# MKE15Z7 register map
Vendor: Freescale Semiconductor, Inc.; Series: Kinetis_E; File version: 1.6
CPU: CM0PLUS r0p0, little endian, no MPU, no FPU, VTOR, 2 interrupt priority bits
Registers are 32-bit, read-write, reset 0x0 unless marked. A register's access mark holds for its fields unless they carry their own. Offsets are from the block's base; [hi:lo] are bit positions; {n}, {i} and the like mark numbered series; 'fields as' and 'values as' point back to an identical list.

## OSC32 — RTC Oscillator
Base 0x40060000; register names take the prefix OSC32_
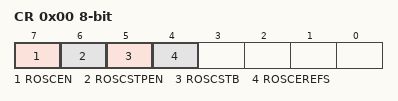
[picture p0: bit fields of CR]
0x00 CR 8-bit — RTC Oscillator Control Register
  [7] ROSCEN — RTC 32k Oscillator enable
    0=Oscillator is disabled; 1=Oscillator is enabled
  [6] ROSCSTPEN — RTC 32k Oscillator stop mode enable
    0=Oscillator is disabled regardless the state of ROSCEN; 1=Oscillator is enabled in Stop mode when ROSCEN is set
  [5] ROSCSTB ro — RTC 32k Oscillator stable flag
    0=RTC 32k oscillator is unstable now and no clock will go out of the block; 1=RTC 32k oscillator is stable
  [4] ROSCEREFS — RTC 32k Oscillator external reference clcok selection
    0=Bypass mode. RTC oscillator selects the external 32k clock.; 1=Crystal mode

## EWM — External Watchdog Monitor
Base 0x40061000; register names take the prefix EWM_
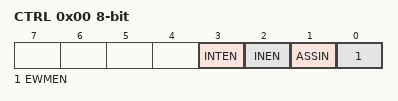
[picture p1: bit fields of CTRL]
0x00 CTRL 8-bit — Control Register
  [3] INTEN — Interrupt Enable.
  [2] INEN — Input Enable.
  [1] ASSIN — EWM_in's Assertion State Select.
  [0] EWMEN — EWM enable.
0x01 SERV 8-bit wo — Service Register
  [7:0] SERVICE — The EWM refresh mechanism requires the CPU to write two values to the SERV register: a first data byte of 0xB4, followed by a second data byte of 0x2C
0x02 CMPL 8-bit — Compare Low Register
  [7:0] COMPAREL — To prevent runaway code from changing this field, software should write to this field after a CPU reset even if the (default) minimum refresh time is required
0x03 CMPH 8-bit reset 0xFF — Compare High Register
  [7:0] COMPAREH — To prevent runaway code from changing this field, software should write to this field after a CPU reset even if the (default) maximum refresh time is required
0x05 CLKPRESCALER 8-bit — Clock Prescaler Register
  [7:0] CLK_DIV — Selected low power clock source for running the EWM counter can be prescaled as below

## TRGMUX0 — Trigger MUX Control
Base 0x40062000
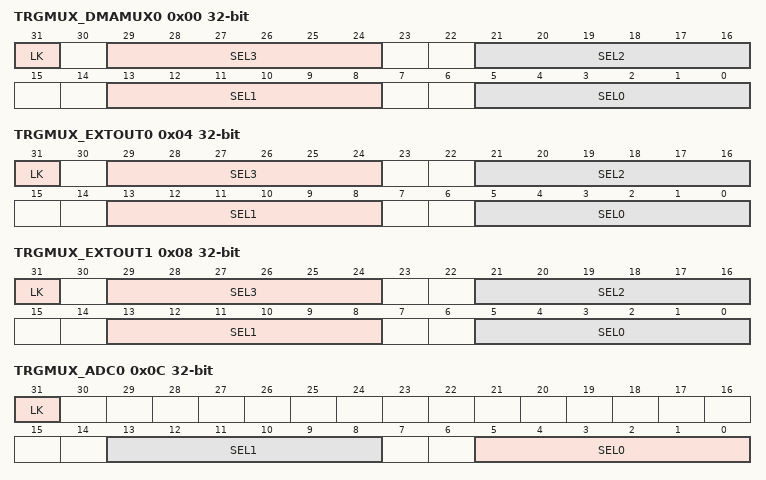
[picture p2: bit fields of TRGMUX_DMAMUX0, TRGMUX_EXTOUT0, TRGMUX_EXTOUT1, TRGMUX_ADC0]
0x00 TRGMUX_DMAMUX0 — TRGMUX Register
  [31] LK ro — Enable
    0=Register can be written; 1=Register cannot be written until the next system Reset
  [8n+5:8n] SEL{n} (n=0..3) — Trigger MUX Input {n} Source Select
0x04 TRGMUX_EXTOUT0 — TRGMUX Register
  fields as TRGMUX_DMAMUX0
0x08 TRGMUX_EXTOUT1 — TRGMUX Register
  fields as TRGMUX_DMAMUX0
0x0C TRGMUX_ADC0 — TRGMUX Register
  [31] LK ro — Enable
    values as TRGMUX_DMAMUX0.LK
  [13:8] SEL1 — Trigger MUX Input 1 Source Select
  [5:0] SEL0 — Trigger MUX Input 0 Source Select
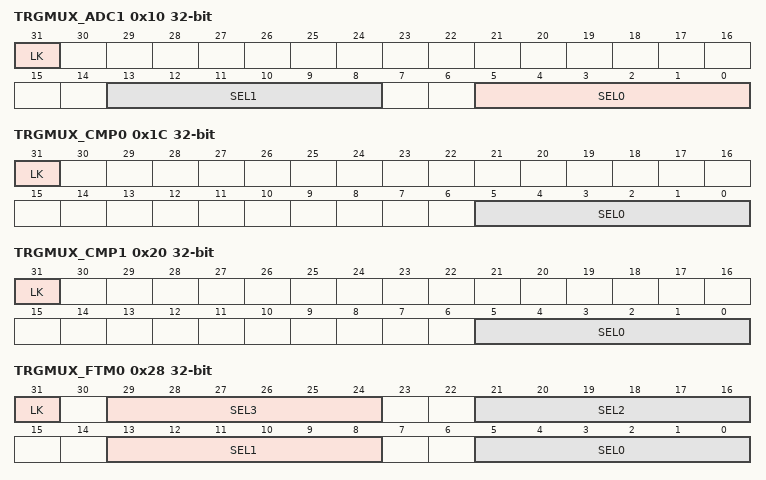
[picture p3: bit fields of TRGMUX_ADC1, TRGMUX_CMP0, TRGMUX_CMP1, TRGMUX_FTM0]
0x10 TRGMUX_ADC1 — TRGMUX Register
  fields as TRGMUX_ADC0
0x1C TRGMUX_CMP0 — TRGMUX Register
  [31] LK ro — Enable
    values as TRGMUX_DMAMUX0.LK
  [5:0] SEL0 — Trigger MUX Input 0 Source Select
0x20 TRGMUX_CMP1 — TRGMUX Register
  fields as TRGMUX_CMP0
0x28 TRGMUX_FTM0 — TRGMUX Register
  fields as TRGMUX_DMAMUX0
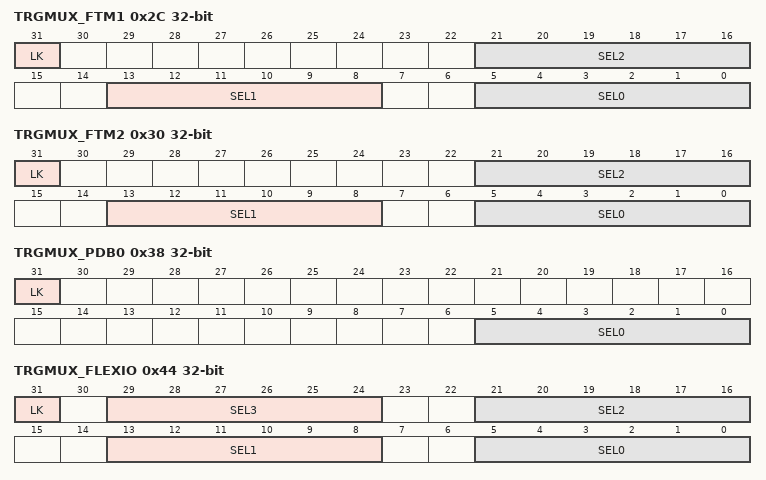
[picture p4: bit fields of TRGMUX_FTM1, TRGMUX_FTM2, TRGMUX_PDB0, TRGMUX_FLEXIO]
0x2C TRGMUX_FTM1 — TRGMUX Register
  [31] LK ro — Enable
    values as TRGMUX_DMAMUX0.LK
  [21:16] SEL2 — Trigger MUX Input 2 Source Select
  [13:8] SEL1 — Trigger MUX Input 1 Source Select
  [5:0] SEL0 — Trigger MUX Input 0 Source Select
0x30 TRGMUX_FTM2 — TRGMUX Register
  fields as TRGMUX_FTM1
0x38 TRGMUX_PDB0 — TRGMUX Register
  fields as TRGMUX_CMP0
0x44 TRGMUX_FLEXIO — TRGMUX Register
  fields as TRGMUX_DMAMUX0
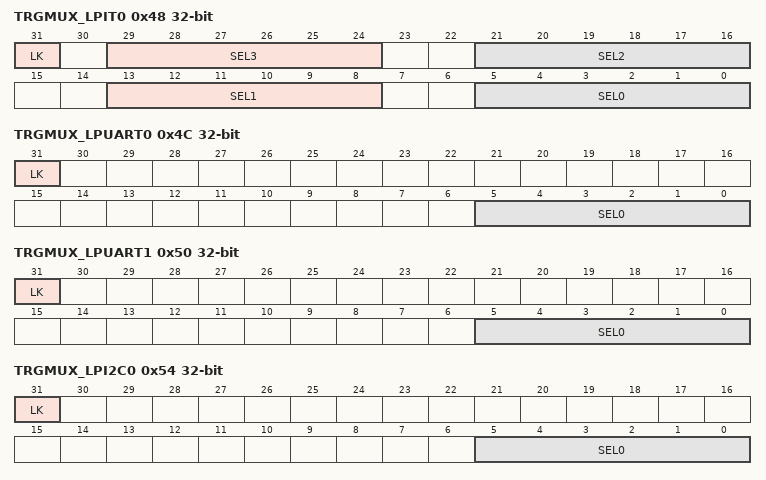
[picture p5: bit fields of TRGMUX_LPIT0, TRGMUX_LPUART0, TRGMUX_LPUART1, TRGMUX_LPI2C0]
0x48 TRGMUX_LPIT0 — TRGMUX Register
  fields as TRGMUX_DMAMUX0
0x4C TRGMUX_LPUART0 — TRGMUX Register
  fields as TRGMUX_CMP0
0x50 TRGMUX_LPUART1 — TRGMUX Register
  fields as TRGMUX_CMP0
0x54 TRGMUX_LPI2C0 — TRGMUX Register
  fields as TRGMUX_CMP0
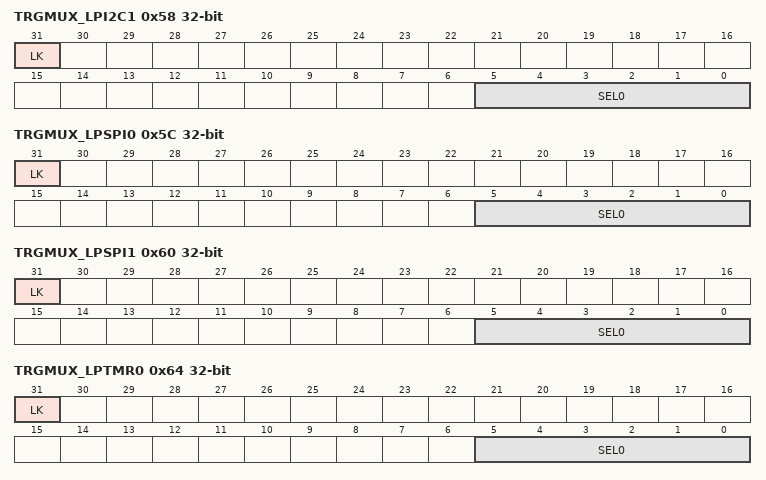
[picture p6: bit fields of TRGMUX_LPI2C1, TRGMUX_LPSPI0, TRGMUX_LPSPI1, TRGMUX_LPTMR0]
0x58 TRGMUX_LPI2C1 — TRGMUX Register
  fields as TRGMUX_CMP0
0x5C TRGMUX_LPSPI0 — TRGMUX Register
  fields as TRGMUX_CMP0
0x60 TRGMUX_LPSPI1 — TRGMUX Register
  fields as TRGMUX_CMP0
0x64 TRGMUX_LPTMR0 — TRGMUX Register
  fields as TRGMUX_CMP0
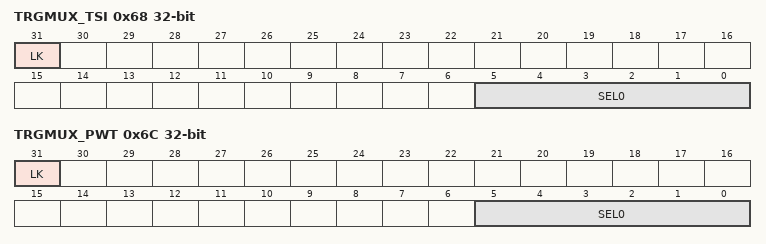
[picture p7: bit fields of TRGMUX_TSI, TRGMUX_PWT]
0x68 TRGMUX_TSI — TRGMUX Register
  fields as TRGMUX_CMP0
0x6C TRGMUX_PWT — TRGMUX Register
  fields as TRGMUX_CMP0
